# ATSAMRH71F20B device description
Architecture: CORTEX-M7; Family: SAMRH; Series: SAMRH71
Registers are 32-bit, read-write, no defined reset value unless marked. A register's access mark holds for its fields unless they carry their own. Offsets are from the block's base; [hi:lo] are bit positions; {n}, {i} and the like mark numbered series.

## MCAN_RXF1E — Rx FIFO 1 Element
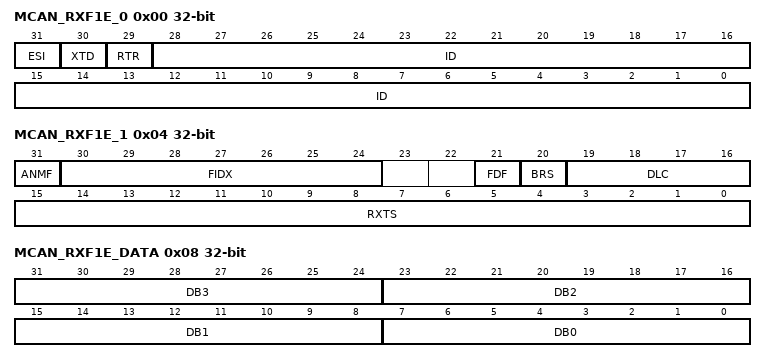
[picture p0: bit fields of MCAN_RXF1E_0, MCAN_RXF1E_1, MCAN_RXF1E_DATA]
0x00 MCAN_RXF1E_0 — Rx FIFO 1 Element 0
  [31] ESI — Error State Indicator
  [30] XTD — Extended Identifier
  [29] RTR — Remote Transmission Request
  [28:0] ID — Identifier
0x04 MCAN_RXF1E_1 — Rx FIFO 1 Element 1
  [31] ANMF — Accepted Non-matching Frame
  [30:24] FIDX — Filter Index
  [21] FDF — FD Format
  [20] BRS — Bit Rate Switch
  [19:16] DLC — Data Length Code
  [15:0] RXTS — Rx Timestamp
0x08 MCAN_RXF1E_DATA — Rx FIFO 1 Element Data
  [8n+7:8n] DB{n} (n=0..3) — Data Byte {n}

## MCAN_TXBE — Tx Buffer Element
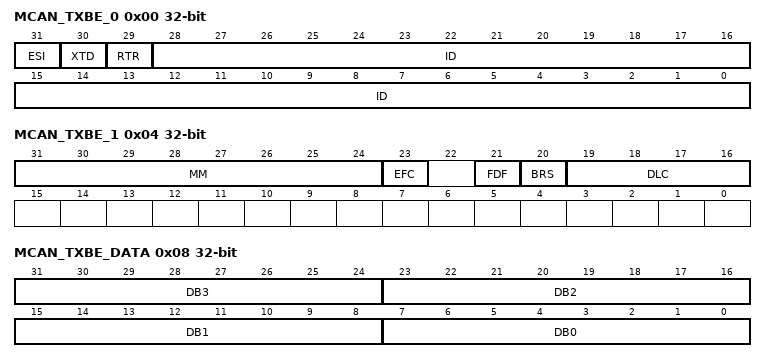
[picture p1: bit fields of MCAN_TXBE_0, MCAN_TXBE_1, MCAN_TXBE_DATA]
0x00 MCAN_TXBE_0 — Tx Buffer Element 0
  [31] ESI — Error State Indicator
  [30] XTD — Extended Identifier
  [29] RTR — Remote Transmission Request
  [28:0] ID — Identifier
0x04 MCAN_TXBE_1 — Tx Buffer Element 1
  [31:24] MM — Message Marker
  [23] EFC — Event FIFO Control
  [21] FDF — FD Format
  [20] BRS — Bit Rate Switch
  [19:16] DLC — Data Length Code
0x08 MCAN_TXBE_DATA — Tx Buffer Element Data
  [8n+7:8n] DB{n} (n=0..3) — Data Byte {n}

## MCAN_TXEFE — Tx Event FIFO Element
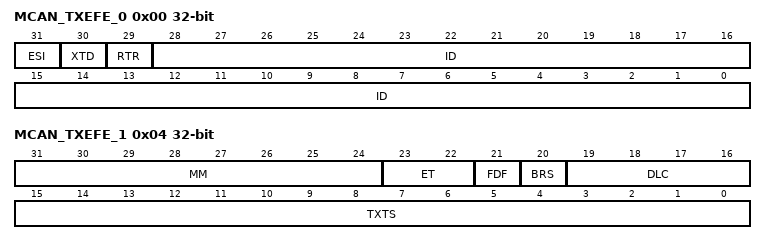
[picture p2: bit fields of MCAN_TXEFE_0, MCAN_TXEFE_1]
0x00 MCAN_TXEFE_0 — Tx Event FIFO Element 0
  [31] ESI — Error State Indicator
  [30] XTD — Extended Identifier
  [29] RTR — Remote Transmission Request
  [28:0] ID — Identifier
0x04 MCAN_TXEFE_1 — Tx Event FIFO Element 1
  [31:24] MM — Message Marker
  [23:22] ET — Event Type
    1=TXE (Tx event); 2=TXC (Transmission in spite of cancellation)
  [21] FDF — FD Format
  [20] BRS — Bit Rate Switch
  [19:16] DLC — Data Length Code
  [15:0] TXTS — Tx Timestamp

## MCAN_SIDFE — Standard Message ID Filter Element
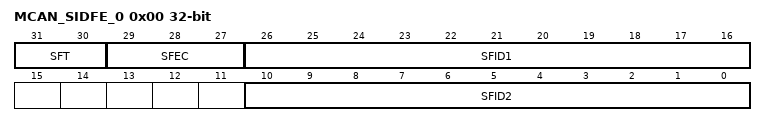
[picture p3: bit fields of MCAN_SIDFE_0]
0x00 MCAN_SIDFE_0 — Standard Message ID Filter Element 0
  [31:30] SFT — Standard Filter Type
    0=RANGE (Range filter from SFID1 to SFID2); 1=DUAL (Dual ID filter for SF1ID or SF2ID); 2=CLASSIC (Classic filter)
  [29:27] SFEC — Standard Filter Element Configuration
    0=DISABLE (Disable filter element); 1=STF0M (Store in Rx FIFO 0 if filter matches); 2=STF1M (Store in Rx FIFO 1 if filter matches); 3=REJECT (Reject ID if filter matches); 4=PRIORITY (Set priority if filter matches); 5=PRIF0M (Set priority and store in FIFO 0 if filter matches); 6=PRIF1M (Set priority and store in FIFO 1 if filter matches); 7=STRXBUF (Store into Rx Buffer)
  [26:16] SFID1 — Standard Filter ID 1
  [10:0] SFID2 — Standard Filter ID 2

## MCAN_XIDFE — Extended Message ID Filter Element
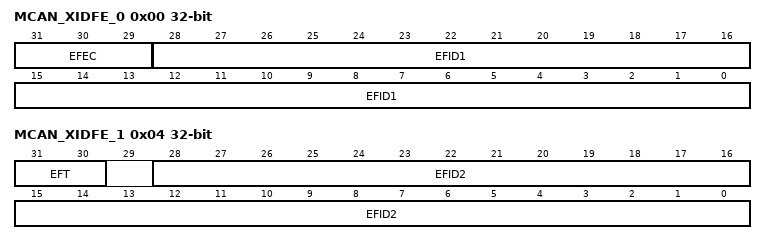
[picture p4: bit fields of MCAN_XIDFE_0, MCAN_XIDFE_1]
0x00 MCAN_XIDFE_0 — Extended Message ID Filter Element 0
  [31:29] EFEC — Extended Filter Element Configuration
    0=DISABLE (Disable filter element); 1=STF0M (Store in Rx FIFO 0 if filter matches); 2=STF1M (Store in Rx FIFO 1 if filter matches); 3=REJECT (Reject ID if filter matches); 4=PRIORITY (Set priority if filter matches); 5=PRIF0M (Set priority and store in FIFO 0 if filter matches); 6=PRIF1M (Set priority and store in FIFO 1 if filter matches); 7=STRXBUF (Store into Rx Buffer)
  [28:0] EFID1 — Extended Filter ID 1
0x04 MCAN_XIDFE_1 — Extended Message ID Filter Element 1
  [31:30] EFT — Extended Filter Type
    0=RANGE (Range filter from EFID1 to EFID2); 1=DUAL (Dual ID filter for EFID1 or EFID2); 2=CLASSIC (Classic filter); 3=RANGE_NO_XIDAM (Range filter from EFID1 to EFID2 with no XIDAM mask)
  [28:0] EFID2 — Extended Filter ID 2

## NMIC — Non-maskable Interrupt Controller
Instances: NMIC 0x400A8000
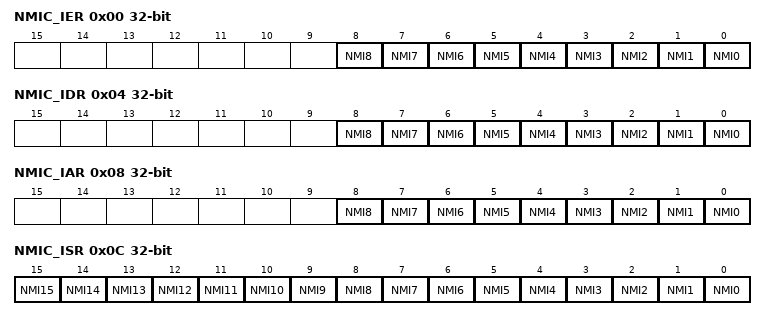
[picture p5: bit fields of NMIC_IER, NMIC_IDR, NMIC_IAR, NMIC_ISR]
0x00 NMIC_IER wo — Interrupt Enable Register
  [n] NMI{n} (n=0..8) — Non-maskable Interrupt {n} Enable
0x04 NMIC_IDR wo — Interrupt Disable Register
  [n] NMI{n} (n=0..8) — Non-maskable Interrupt {n} Disable
0x08 NMIC_IAR ro — Interrupt Active Register
  [n] NMI{n} (n=0..8) — Active Interrupt {n}
0x0C NMIC_ISR ro — Interrupt Status Register
  [n] NMI{n} (n=0..15) — Non-maskable Interrupt Source {n} Pending (cleared on read)
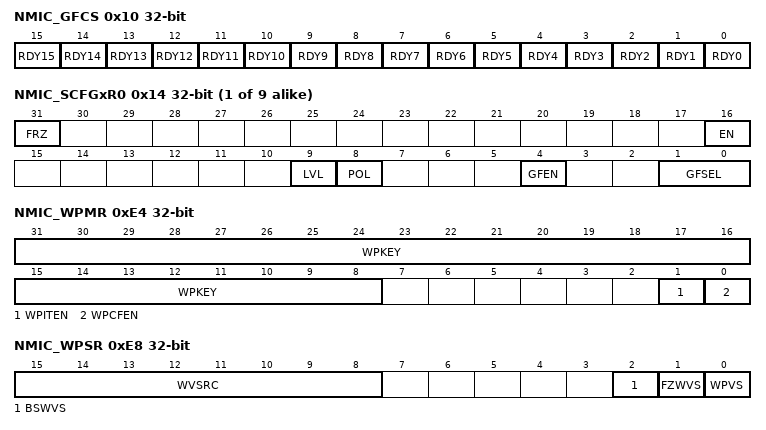
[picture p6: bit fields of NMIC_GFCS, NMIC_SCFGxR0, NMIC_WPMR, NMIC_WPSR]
0x10 NMIC_GFCS ro — Glitch Filter Configuration Status Register
  [n] RDY{n} (n=0..15) — Filter {n} Configuration Ready
{0x14+4i} NMIC_SCFGxR{i} (i=0..8) — Source Configuration Register 0 {i}
  [31] FRZ — Interrupt Line Freeze
  [16] EN — Source Enable
  [9] LVL — Level Detection (LVL bit is read-only in NMIC_SCFG0 to 8)
  [8] POL — Polarity (POL bit is read-only in NMIC_SCFG0 to 8)
  [4] GFEN — Glitch Filter Enable (GFEN bit is read-only in NMIC_SCFG0 to 8)
  [1:0] GFSEL — Glitch Filter Selector (GFSEL field is read-only in NMIC_SCFG0 to 8)
0xE4 NMIC_WPMR — Write Protection Mode Register
  [31:8] WPKEY — Write Protection Key
    0x4E4D49=PASSWD (Writing any other value in this field aborts the write operation of the WPCFEN and WPITEN bit. Always reads as 0.)
  [1] WPITEN — Write Protection Interrupt Enable
  [0] WPCFEN — Write Protection Configuration Enable
0xE8 NMIC_WPSR ro — Write Protection Status Register
  [15:8] WVSRC — Write Violation Source
  [2] BSWVS — Busy Register Write Violation Status
  [1] FZWVS — Frozen Register Write Violation Status
  [0] WPVS — Write Protection Register Violation Status
